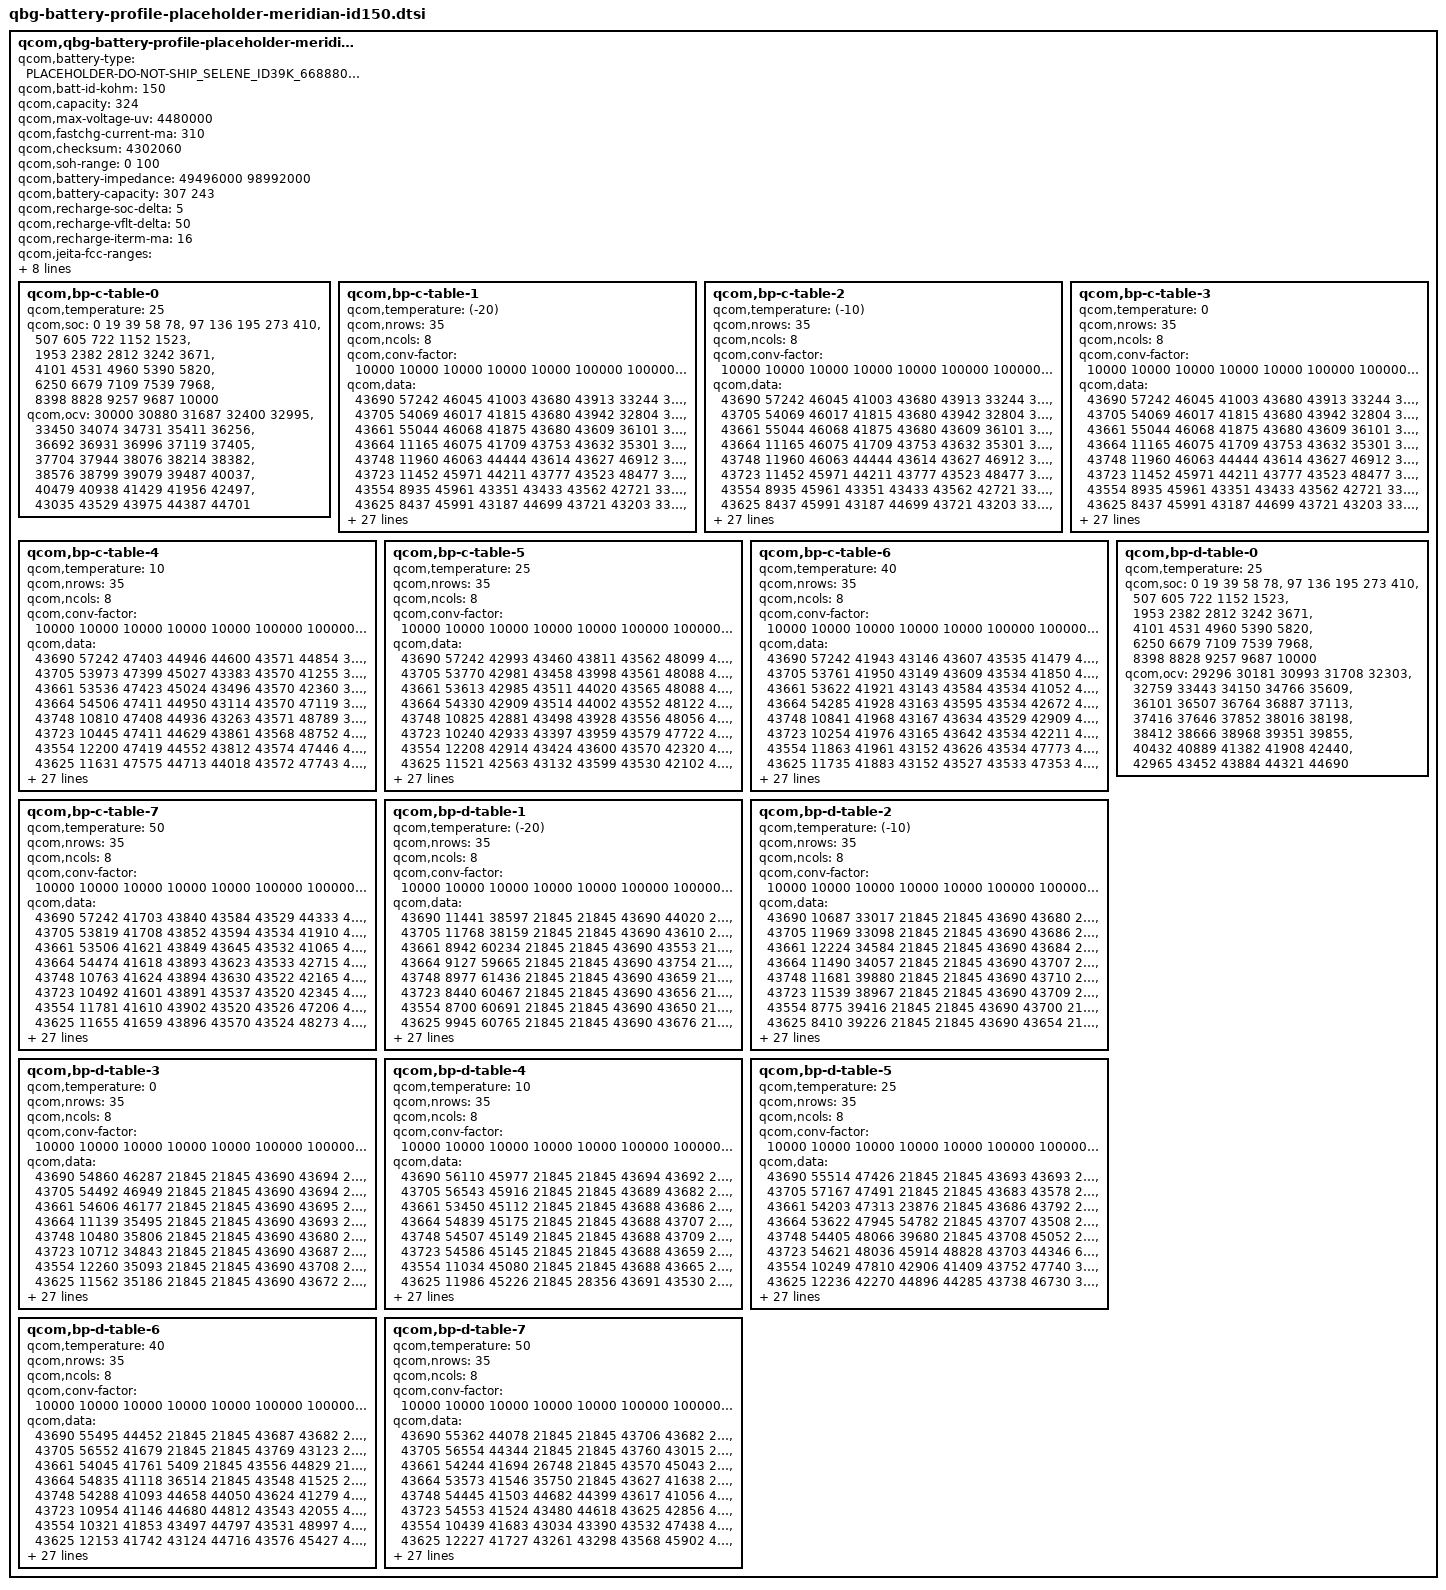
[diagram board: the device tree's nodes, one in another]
/*QBG Profiling Rev. 2.7*/

qcom,qbg-battery-profile-placeholder-meridian-id150 {
	qcom,battery-type = "PLACEHOLDER-DO-NOT-SHIP_SELENE_ID39K_6688801_GOOGLE_310MAH_AVERAGED_MASTERSLAVE_JUL5TH2023";
	qcom,batt-id-kohm = <150>;
	qcom,capacity = <324>;
	qcom,max-voltage-uv = <4480000>;
	qcom,fastchg-current-ma = <310>;
	qcom,checksum = <4302060>; /*@5, 0.005V, 4% */
	qcom,soh-range = <0 100>;
	/*Nominal_Impedance in 10nohm @ SOC 50% 25C* 0:fresh cell, 1: aged cell*/
	qcom,battery-impedance = <49496000 98992000>;
	/*Nominal_Capacity in mAh. 0: fresh cell, 1:aged cell*/ 
	qcom,battery-capacity = <307 243>;
	/*SOC delta (in percent) dropped from EOC SOC to enable recharge*/ 
	qcom,recharge-soc-delta =<5>;
	/*vfloat delta (in mV) dropped from regular vfloat in recharge*/ 
	qcom,recharge-vflt-delta =<50>;
	/*termination current (in mA) in recharge*/ 
	qcom,recharge-iterm-ma = <16>;

	qcom,jeita-fcc-ranges = <0  100 125000
				100 150 175000
				150 250 450000
				250 410 500000
				410 450 125000>;

	qcom,jeita-fv-ranges = <0   100 4480000
				100 150 4480000
				150 250 4480000
				250 410 4480000
				410 450 4480000>;

	/* COOL = 10 DegC, WARM = 41 DegC */
	qcom,jeita-soft-thresholds = <0x2b8a 0x14de>;
	/* COLD = 0 DegC, HOT = 45 DegC */
	qcom,jeita-hard-thresholds = <0x3257 0x128c>;
	/* COOL = 12 DegC, WARM = 39 DegC*/
	qcom,jeita-soft-hys-thresholds = <0x2a0b 0x161b>;
	qcom,jeita-soft-fcc-ua = <125000 125000>;
	qcom,jeita-soft-fv-uv = <4480000 4480000>;

	qcom,bp-c-table-0 {
		qcom,temperature = <25>;
		qcom,soc = <    0    19    39    58    78>,
			<   97   136   195   273   410>,
			<  507   605   722  1152  1523>,
			< 1953  2382  2812  3242  3671>,
			< 4101  4531  4960  5390  5820>,
			< 6250  6679  7109  7539  7968>,
			< 8398  8828  9257  9687 10000>;
		qcom,ocv = <30000 30880 31687 32400 32995>,
			<33450 34074 34731 35411 36256>,
			<36692 36931 36996 37119 37405>,
			<37704 37944 38076 38214 38382>,
			<38576 38799 39079 39487 40037>,
			<40479 40938 41429 41956 42497>,
			<43035 43529 43975 44387 44701>;
	};
	qcom,bp-c-table-1 {
		qcom,temperature = <(-20)>;
		qcom,nrows = <35>;
		qcom,ncols = <8>;
		qcom,conv-factor = <10000 10000 10000 10000 10000 100000 100000 10000>;
		qcom,data = <43690 57242 46045 41003 43680 43913 33244 34599>,
			<43705 54069 46017 41815 43680 43942 32804 34722>,
			<43661 55044 46068 41875 43680 43609 36101 34521>,
			<43664 11165 46075 41709 43753 43632 35301 33149>,
			<43748 11960 46063 44444 43614 43627 46912 33180>,
			<43723 11452 45971 44211 43777 43523 48477 32831>,
			<43554  8935 45961 43351 43433 43562 42721 33734>,
			<43625  8437 45991 43187 44699 43721 43203 33437>,
			<43963  9790 45992 43850 44693 43729 43803 36155>,
			<43824  9725 45680 44006 44782 43576 43976 35881>,
			<43857 15044 45571 43629 44643 43583 43941 35975>,
			<43255 14877 45585 43938 44576 43574 43905 36676>,
			<43128 14965 45627 43930 44763 43530 44015 36683>,
			<44586 15107 45588 43289 43104 43573 44521 35883>,
			<44889 14458 45808 41656 43901 43552 47334 33716>,
			<44299 14687 45745 41917 43157 43566 48855 33644>,
			<41956 15888 48403 41744 43056 43563 47202 33626>,
			<41046 16257 48398 41129 43080 43733 47938 32907>,
			<42496 16189 48598 41116 43403 43732 48051 33009>,
			<42237 15549 48630 41183 43509 43735 48102 32794>,
			<47791 15384 48638 41059 43298 43734 47475 33200>,
			<47897 15657 48614 41381 43303 43734 48505 33254>,
			<47562 12898 48629 41356 43440 43729 45910 32886>,
			<49060 12334 48584 41354 43129 43743 42049 32793>,
			<48150 13964 48483 41244 43422 43719 41116 34452>,
			<45760 14203 45821 42538 43294 43724 41628 33999>,
			<45245 13631 46001 42929 44736 43723 44068 39443>,
			<45423  3013 45949 42759 44996 43764 45038 39383>,
			<47065  2551 45262 42210 44051 43767 44767 40056>,
			<46474  4041 45442 42045 41493 43765 43315 36974>,
			<35428  3544 45406 42414 41227 43720 43455 60036>,
			<35030   984 46670 42409 47862 43726 43051 60731>,
			<36483   400 46907 42028 45649 43725 43199 65188>,
			<36733  1620 46332 41865 34867 43588 43921 63376>,
			<36282  1213 46485 43374 45496 43756 43544 65526>;
	};
	qcom,bp-c-table-2 {
		qcom,temperature = <(-10)>;
		qcom,nrows = <35>;
		qcom,ncols = <8>;
		qcom,conv-factor = <10000 10000 10000 10000 10000 100000 100000 10000>;
		qcom,data = <43690 57242 46045 41003 43680 43913 33244 34599>,
			<43705 54069 46017 41815 43680 43942 32804 34722>,
			<43661 55044 46068 41875 43680 43609 36101 34521>,
			<43664 11165 46075 41709 43753 43632 35301 33149>,
			<43748 11960 46063 44444 43614 43627 46912 33180>,
			<43723 11452 45971 44211 43777 43523 48477 32831>,
			<43554  8935 45961 43351 43433 43562 42721 33734>,
			<43625  8437 45991 43187 44699 43721 43203 33437>,
			<43963  9790 45992 43850 44693 43729 43803 36155>,
			<43824  9725 45680 44006 44782 43576 43976 35881>,
			<43857 15044 45571 43629 44643 43583 43941 35975>,
			<43255 14877 45585 43938 44576 43574 43905 36676>,
			<43128 14965 45627 43930 44763 43530 44015 36683>,
			<44586 15107 45588 43289 43104 43573 44521 35883>,
			<44889 14458 45808 41656 43901 43552 47334 33716>,
			<44299 14687 45745 41917 43157 43566 48855 33644>,
			<41956 15888 48403 41744 43056 43563 47202 33626>,
			<41046 16257 48398 41129 43080 43733 47938 32907>,
			<42496 16189 48598 41116 43403 43732 48051 33009>,
			<42237 15549 48630 41183 43509 43735 48102 32794>,
			<47791 15384 48638 41059 43298 43734 47475 33200>,
			<47897 15657 48614 41381 43303 43734 48505 33254>,
			<47562 12898 48629 41356 43440 43729 45910 32886>,
			<49060 12334 48584 41354 43129 43743 42049 32793>,
			<48150 13964 48483 41244 43422 43719 41116 34452>,
			<45760 14203 45821 42538 43294 43724 41628 33999>,
			<45245 13631 46001 42929 44736 43723 44068 39443>,
			<45423  3013 45949 42759 44996 43764 45038 39383>,
			<47065  2551 45262 42210 44051 43767 44767 40056>,
			<46474  4041 45442 42045 41493 43765 43315 36974>,
			<35428  3544 45406 42414 41227 43720 43455 60036>,
			<35030   984 46670 42409 47862 43726 43051 60731>,
			<36483   400 46907 42028 45649 43725 43199 65188>,
			<36733  1620 46332 41865 34867 43588 43921 63376>,
			<36282  1213 46485 43374 45496 43756 43544 65526>;
	};
	qcom,bp-c-table-3 {
		qcom,temperature = <0>;
		qcom,nrows = <35>;
		qcom,ncols = <8>;
		qcom,conv-factor = <10000 10000 10000 10000 10000 100000 100000 10000>;
		qcom,data = <43690 57242 46045 41003 43680 43913 33244 34599>,
			<43705 54069 46017 41815 43680 43942 32804 34722>,
			<43661 55044 46068 41875 43680 43609 36101 34521>,
			<43664 11165 46075 41709 43753 43632 35301 33149>,
			<43748 11960 46063 44444 43614 43627 46912 33180>,
			<43723 11452 45971 44211 43777 43523 48477 32831>,
			<43554  8935 45961 43351 43433 43562 42721 33734>,
			<43625  8437 45991 43187 44699 43721 43203 33437>,
			<43963  9790 45992 43850 44693 43729 43803 36155>,
			<43824  9725 45680 44006 44782 43576 43976 35881>,
			<43857 15044 45571 43629 44643 43583 43941 35975>,
			<43255 14877 45585 43938 44576 43574 43905 36676>,
			<43128 14965 45627 43930 44763 43530 44015 36683>,
			<44586 15107 45588 43289 43104 43573 44521 35883>,
			<44889 14458 45808 41656 43901 43552 47334 33716>,
			<44299 14687 45745 41917 43157 43566 48855 33644>,
			<41956 15888 48403 41744 43056 43563 47202 33626>,
			<41046 16257 48398 41129 43080 43733 47938 32907>,
			<42496 16189 48598 41116 43403 43732 48051 33009>,
			<42237 15549 48630 41183 43509 43735 48102 32794>,
			<47791 15384 48638 41059 43298 43734 47475 33200>,
			<47897 15657 48614 41381 43303 43734 48505 33254>,
			<47562 12898 48629 41356 43440 43729 45910 32886>,
			<49060 12334 48584 41354 43129 43743 42049 32793>,
			<48150 13964 48483 41244 43422 43719 41116 34452>,
			<45760 14203 45821 42538 43294 43724 41628 33999>,
			<45245 13631 46001 42929 44736 43723 44068 39443>,
			<45423  3013 45949 42759 44996 43764 45038 39383>,
			<47065  2551 45262 42210 44051 43767 44767 40056>,
			<46474  4041 45442 42045 41493 43765 43315 36974>,
			<35428  3544 45406 42414 41227 43720 43455 60036>,
			<35030   984 46670 42409 47862 43726 43051 60731>,
			<36483   400 46907 42028 45649 43725 43199 65188>,
			<36733  1620 46332 41865 34867 43588 43921 63376>,
			<36282  1213 46485 43374 45496 43756 43544 65526>;
	};
	qcom,bp-c-table-4 {
		qcom,temperature = <10>;
		qcom,nrows = <35>;
		qcom,ncols = <8>;
		qcom,conv-factor = <10000 10000 10000 10000 10000 100000 100000 10000>;
		qcom,data = <43690 57242 47403 44946 44600 43571 44854 34827>,
			<43705 53973 47399 45027 43383 43570 41255 35002>,
			<43661 53536 47423 45024 43496 43570 42360 35804>,
			<43664 54506 47411 44950 43114 43570 47119 35442>,
			<43748 10810 47408 44936 43263 43571 48789 35474>,
			<43723 10445 47411 44629 43861 43568 48752 46385>,
			<43554 12200 47419 44552 43812 43574 47446 46288>,
			<43625 11631 47575 44713 44018 43572 47743 47081>,
			<43963  8251 47493 43108 43167 43573 44587 46808>,
			<43824 10055 47173 43212 43164 43526 43506 45522>,
			<43857  9520 47178 43244 43158 43538 43484 45500>,
			<43255 15070 47120 43592 43508 43596 44018 45104>,
			<43128 14849 47154 43960 43494 43636 43981 45268>,
			<44586 15254 47144 44777 43972 43532 42873 45375>,
			<44889 14537 47250 44883 43887 43552 47991 47024>,
			<44299 14628 47936 44230 43139 43565 47160 47095>,
			<41956 16093 47921 44131 43160 43566 47115 47074>,
			<41046 15942 48077 44118 43256 43566 47960 47072>,
			<42496 16334 48020 44448 43050 43561 42283 47078>,
			<42237 16220 48053 44462 43128 43563 42551 47043>,
			<47791 15369 48034 44452 43408 43733 42743 46879>,
			<47897 15809 47706 44525 43306 43732 42065 46216>,
			<47562 13016 47739 44290 43472 43563 45605 46310>,
			<49060 12473 47632 44402 43026 43566 35584 46860>,
			<48150 14068 47643 44472 43140 43734 41169 46825>,
			<45760 13476 47628 44528 43261 43741 41907 46618>,
			<45245 13689 47621 44301 43054 43737 44374 47080>,
			<45423  2847 47706 41513 43448 43713 44247 46500>,
			<47065  2328 48118 41873 43383 43714 45046 35739>,
			<46474  3950 47951 41855 44613 43714 44599 35084>,
			<35428  3443 47144 41195 44044 43712 43341 35914>,
			<35030   889 47491 41206 41787 43716 43405 33256>,
			<36483   316 47473 41122 42368 43743 43048 39145>,
			<36733  1942 48665 44371 49000 43533 43888 37871>,
			<36282  1230 48944 44544 48832 43727 43937 40241>;
	};
	qcom,bp-c-table-5 {
		qcom,temperature = <25>;
		qcom,nrows = <35>;
		qcom,ncols = <8>;
		qcom,conv-factor = <10000 10000 10000 10000 10000 100000 100000 10000>;
		qcom,data = <43690 57242 42993 43460 43811 43562 48099 48895>,
			<43705 53770 42981 43458 43998 43561 48088 48830>,
			<43661 53613 42985 43511 44020 43565 48088 47482>,
			<43664 54330 42909 43514 44002 43552 48122 47399>,
			<43748 10825 42881 43498 43928 43556 48056 47584>,
			<43723 10240 42933 43397 43959 43579 47722 47520>,
			<43554 12208 42914 43424 43600 43570 42320 47166>,
			<43625 11521 42563 43132 43599 43530 42102 47268>,
			<43963  8441 42601 43047 43602 43521 41865 47883>,
			<43824  9994 42551 43165 43910 43536 44895 48110>,
			<43857  9726 42541 43199 43908 43626 44886 47708>,
			<43255 15081 42716 43150 43624 43536 41255 47649>,
			<43128 14894 42697 43154 43520 43548 42805 47834>,
			<44586 14933 42644 43036 43969 43522 41798 47904>,
			<44889 14519 42671 43497 43872 43583 41098 47340>,
			<44299 14818 41341 43306 43857 43570 41286 47144>,
			<41956 16018 41223 43288 43799 43583 42247 47335>,
			<41046 15894 41262 43366 43804 43577 42331 47260>,
			<42496 16364 41461 43330 43876 43583 42888 47331>,
			<42237 16196 41364 43297 43222 43578 44111 47317>,
			<47791 15386 41358 43464 43416 43552 44200 47218>,
			<47897 15653 41383 43476 43456 43565 44518 47511>,
			<47562 12813 41040 43359 43495 43553 42807 47613>,
			<49060 12437 41030 44698 43218 43576 47915 47176>,
			<48150 14031 41026 43331 43795 43554 41852 47981>,
			<45760 13493 41038 43367 43841 43563 44244 47985>,
			<45245 13632 41026 44718 43146 43729 45009 47345>,
			<45423  2943 41031 44769 43201 43740 44563 47531>,
			<47065  2382 41043 44567 43060 43741 44589 47383>,
			<46474  3243 41399 44918 43450 43743 44549 49107>,
			<35428   689 41422 44271 44683 43741 44722 48579>,
			<35030   163 41239 44088 44816 43732 43316 45836>,
			<36483   365 42627 44093 41878 43556 43402 46850>,
			<36733  1993 42524 44667 44290 43578 43380 45144>,
			<36282  1079 42776 43107 42372 43561 43929 35588>;
	};
	qcom,bp-c-table-6 {
		qcom,temperature = <40>;
		qcom,nrows = <35>;
		qcom,ncols = <8>;
		qcom,conv-factor = <10000 10000 10000 10000 10000 100000 100000 10000>;
		qcom,data = <43690 57242 41943 43146 43607 43535 41479 42790>,
			<43705 53761 41950 43149 43609 43534 41850 42964>,
			<43661 53622 41921 43143 43584 43534 41052 42949>,
			<43664 54285 41928 43163 43595 43534 42672 42955>,
			<43748 10841 41968 43167 43634 43529 42909 43000>,
			<43723 10254 41976 43165 43642 43534 42211 42990>,
			<43554 11863 41961 43152 43626 43534 47773 42895>,
			<43625 11735 41883 43152 43527 43533 47353 42589>,
			<43963  8380 41866 43148 43568 43524 48815 42526>,
			<43824 10226 41888 43191 43581 43548 47104 42540>,
			<43857  9656 41899 43901 43533 43619 42160 42647>,
			<43255 15024 41552 43983 43542 43632 41791 41313>,
			<43128 15042 41560 43976 43529 43641 41317 41221>,
			<44586 14949 41550 43884 43823 43629 44270 42579>,
			<44889 15170 41573 43847 43879 43537 44204 42997>,
			<44299 14779 41494 43149 43851 43538 41606 42801>,
			<41956 14684 41475 43241 43828 43544 42857 42946>,
			<41046 15927 41533 43141 43980 43524 42638 42943>,
			<42496 16272 41518 43219 44020 43534 41459 42978>,
			<42237 16199 41669 43214 43850 43525 44261 42783>,
			<47791 15380 41718 43901 43089 43544 43342 42162>,
			<47897 15619 41700 43877 43493 43526 44582 42203>,
			<47562 12903 41705 43152 43443 43532 41584 42207>,
			<49060 12510 41622 43229 43174 43535 42751 42853>,
			<48150 14034 41619 43253 43979 43535 41180 42565>,
			<45760 13463 41629 43189 43835 43528 44633 42573>,
			<45245  2720 41629 43207 43780 43570 44640 42944>,
			<45423  2896 41619 43117 43854 43557 44569 42148>,
			<47065  3756 41620 43449 43154 43554 44679 42089>,
			<46474  3252 41699 43318 43254 43563 44544 42283>,
			<35428   667 41719 44732 43455 43734 43333 47733>,
			<35030   191 41684 44592 43354 43555 44731 47359>,
			<36483   357 41475 44558 44865 43529 43369 48684>,
			<36733  2014 41536 43399 44565 43575 44792 47952>,
			<36282  1049 41774 43235 42676 43544 43817 45952>;
	};
	qcom,bp-c-table-7 {
		qcom,temperature = <50>;
		qcom,nrows = <35>;
		qcom,ncols = <8>;
		qcom,conv-factor = <10000 10000 10000 10000 10000 100000 100000 10000>;
		qcom,data = <43690 57242 41703 43840 43584 43529 44333 42662>,
			<43705 53819 41708 43852 43594 43534 41910 41309>,
			<43661 53506 41621 43849 43645 43532 41065 41288>,
			<43664 54474 41618 43893 43623 43533 42715 41319>,
			<43748 10763 41624 43894 43630 43522 42165 41234>,
			<43723 10492 41601 43891 43537 43520 42345 41225>,
			<43554 11781 41610 43902 43520 43526 47206 41431>,
			<43625 11655 41659 43896 43570 43524 48273 41471>,
			<43963  9065 41646 43900 43555 43546 46069 41363>,
			<43824 10157 44377 43799 43561 43537 48172 41041>,
			<43857  9320 44353 43827 43577 43620 47723 41086>,
			<43255  9587 44364 43967 43523 43615 41861 41190>,
			<43128 15000 44363 43944 43569 43609 41154 41090>,
			<44586 14907 44402 43818 43983 43635 44884 41256>,
			<44889 15119 44390 43833 43835 43644 44895 41244>,
			<44299 14463 44395 43828 43804 43647 44089 41290>,
			<41956 14614 44319 43787 43803 43640 41790 41339>,
			<41046 15912 44291 43815 44026 43617 41972 41457>,
			<42496 16263 44343 43876 43935 43538 41756 41251>,
			<42237 16204 44324 43194 43987 43543 44453 42659>,
			<47791 15380 44331 44021 43033 43646 43483 42713>,
			<47897 15643 44508 43925 43446 43617 43368 42513>,
			<47562 12874 44484 43815 43083 43626 44522 42523>,
			<49060 12321 44483 43890 43873 43540 42679 42665>,
			<48150 13867 44492 43896 43904 43543 41241 41454>,
			<45760 13539 44494 43788 44009 43538 45015 41367>,
			<45245  2737 44494 43891 43997 43526 44651 41234>,
			<45423  2213 44489 43188 43801 43531 44796 42727>,
			<47065  3763 44493 43065 43902 43583 44633 42589>,
			<46474  3226 44487 43098 43177 43556 44942 42814>,
			<35428   657 44508 43474 43213 43567 44639 42044>,
			<35030   181 44322 43323 43496 43552 44689 42248>,
			<36483   369 44302 43299 44660 43574 43271 48018>,
			<36733  2002 44390 43016 43272 43520 44941 42378>,
			<36282  1130 41620 43998 41591 43621 44018 47390>;
	};
	qcom,bp-d-table-0 {
		qcom,temperature = <25>;
		qcom,soc = <    0    19    39    58    78>,
			<   97   136   195   273   410>,
			<  507   605   722  1152  1523>,
			< 1953  2382  2812  3242  3671>,
			< 4101  4531  4960  5390  5820>,
			< 6250  6679  7109  7539  7968>,
			< 8398  8828  9257  9687 10000>;
		qcom,ocv = <29296 30181 30993 31708 32303>,
			<32759 33443 34150 34766 35609>,
			<36101 36507 36764 36887 37113>,
			<37416 37646 37852 38016 38198>,
			<38412 38666 38968 39351 39855>,
			<40432 40889 41382 41908 42440>,
			<42965 43452 43884 44321 44690>;
	};
	qcom,bp-d-table-1 {
		qcom,temperature = <(-20)>;
		qcom,nrows = <35>;
		qcom,ncols = <8>;
		qcom,conv-factor = <10000 10000 10000 10000 10000 100000 100000 10000>;
		qcom,data = <43690 11441 38597 21845 21845 43690 44020 21845>,
			<43705 11768 38159 21845 21845 43690 43610 21845>,
			<43661  8942 60234 21845 21845 43690 43553 21845>,
			<43664  9127 59665 21845 21845 43690 43754 21845>,
			<43748  8977 61436 21845 21845 43690 43659 21845>,
			<43723  8440 60467 21845 21845 43690 43656 21845>,
			<43554  8700 60691 21845 21845 43690 43650 21845>,
			<43625  9945 60765 21845 21845 43690 43676 21845>,
			<43963 10179 60735 21845 18154 43690 43770 21845>,
			<43824  9410 60480 21845 50402 43690 43554 21845>,
			<43857  9335 61424 21845 58345 43690 43538 21845>,
			<43255  9618 59792 21845 39247 43690 43585 21845>,
			<43128  9525 60361 21845 36472 43690 44000 21845>,
			<44586 14874 37016 15248 48556 43691 43217 21845>,
			<44889 15308 37786 49431 45501 43691 43102 21845>,
			<44299 15199 40755 57586 48384 43688 43429 21845>,
			<41956 14379 39331 40399 47211 43689 43483 32111>,
			<41046 14776 39543 33182 41984 43694 43380  7668>,
			<42496 14598 34275 35301 41284 43695 44678  2958>,
			<42237 16118 33953 46957 41124 43692 44751 14910>,
			<47791 16308 34703 46076 41542 43693 44747 10592>,
			<47897 16209 33099 48260 44355 43683 44592 54027>,
			<47562 15447 33186 48748 44225 43681 44266 56067>,
			<49060 13038 32989 48874 44918 43686 41670 51188>,
			<48150 13176 32898 47475 44218 43684 41191 49649>,
			<45760 12605 32930 47571 44057 43706 41401 49574>,
			<45245 14126 33606 47559 44301 43704 41359 49606>,
			<45423 13619 33656 47482 41683 43711 41404 50916>,
			<47065  2938 33556 47455 41504 43669 42757 51158>,
			<46474  3758 33542 48737 41904 43669 42144 50207>,
			<35428  3207 33587 49144 41752 43668 42788 50545>,
			<35030   663 33747 49147 41754 43775 42533 55864>,
			<36483   153 33770 48946 41549 43770 41159 55975>,
			<36733   325 33351 48610 44052 43693 44874 51098>,
			<36282  1930 33285 45627 44846 43690 43394 49544>;
	};
	qcom,bp-d-table-2 {
		qcom,temperature = <(-10)>;
		qcom,nrows = <35>;
		qcom,ncols = <8>;
		qcom,conv-factor = <10000 10000 10000 10000 10000 100000 100000 10000>;
		qcom,data = <43690 10687 33017 21845 21845 43690 43680 21845>,
			<43705 11969 33098 21845 21845 43690 43686 21845>,
			<43661 12224 34584 21845 21845 43690 43684 21845>,
			<43664 11490 34057 21845 21845 43690 43707 21845>,
			<43748 11681 39880 21845 21845 43690 43710 21845>,
			<43723 11539 38967 21845 21845 43690 43709 21845>,
			<43554  8775 39416 21845 21845 43690 43700 21845>,
			<43625  8410 39226 21845 21845 43690 43654 21845>,
			<43963  9877 39333 21845     3 43690 43768 21845>,
			<43824  9415 39817 21845 40756 43690 43607 21845>,
			<43857  9610 34099 21845 46200 43690 43819 21845>,
			<43255  9516 34604 25584 48654 43690 43192 21845>,
			<43128  9587 33234 50113 42951 43691 43112 21845>,
			<44586 14918 36716 45683 44194 43689 45026 14611>,
			<44889 15139 36539 45217 41916 43695 44786 11758>,
			<44299 14512 35050 48640 44343 43683 44642 50413>,
			<41956 14387 35724 47784 44206 43706 44954 62683>,
			<41046 14768 35330 42947 44578 43657 44280 65307>,
			<42496 14604 35539 42656 43277 43669 44333 64025>,
			<42237 16119 35525 41391 43458 43746 41536 59380>,
			<47791 16357 35562 41024 43077 43717 42033 57655>,
			<47897 15423 35576 41360 43512 43728 48984 57790>,
			<47562 15694 35476 41443 43343 43735 47389 57347>,
			<49060 13304 35553 41438 44736 43562 47680 57406>,
			<48150 12381 35564 41306 44621 43563 47795 57442>,
			<45760 13945 35477 42549 45009 43563 42280 57797>,
			<45245 13436 35555 42998 44197 43734 42191 59009>,
			<45423  2651 35511 42224 44231 43740 42165 59265>,
			<47065  2484 35465 42477 44098 43717 42848 58618>,
			<46474  4066 35505 47780 44488 43725 42589 58671>,
			<35428  3577 35492 47739 44391 43722 41326 64121>,
			<35030   909 46450 48078 44397 43763 41815 64331>,
			<36483   122 46387 47977 44114 43749 41536 64325>,
			<36733  1557 46535 47967 44790 43752 41672 64125>,
			<36282  1036 46541 47937 43429 43676 41724 58849>;
	};
	qcom,bp-d-table-3 {
		qcom,temperature = <0>;
		qcom,nrows = <35>;
		qcom,ncols = <8>;
		qcom,conv-factor = <10000 10000 10000 10000 10000 100000 100000 10000>;
		qcom,data = <43690 54860 46287 21845 21845 43690 43694 21845>,
			<43705 54492 46949 21845 21845 43690 43694 21845>,
			<43661 54606 46177 21845 21845 43690 43695 21845>,
			<43664 11139 35495 21845 21845 43690 43693 21845>,
			<43748 10480 35806 21845 21845 43690 43680 21845>,
			<43723 10712 34843 21845 21845 43690 43687 21845>,
			<43554 12260 35093 21845 21845 43690 43708 21845>,
			<43625 11562 35186 21845 21845 43690 43672 21845>,
			<43963  9085 35230 21845 10917 43690 43729 21845>,
			<43824 10153 35762 21845 45680 43690 43834 21845>,
			<43857  9279 46356 53993 42123 43690 43228 21845>,
			<43255  9715 46182 37747 41931 43691 43303 16565>,
			<43128  9498 46865 46770 44208 43688 44590  3867>,
			<44586 15040 45125 41696 43443 43683 44174 64396>,
			<44889 15263 45894 41793 43016 43703 41774 57737>,
			<44299 14542 46066 41934 43094 43745 45594 61065>,
			<41956 14731 45959 41511 43411 43743 45121 38308>,
			<41046 14628 46057 41630 43083 43729 48304 36970>,
			<42496 16044 45993 44356 43066 43732 47939 40220>,
			<42237 15970 45982 44383 43040 43561 47436 40127>,
			<47791 16149 45993 41643 43122 43567 48890 40845>,
			<47897 15462 45989 41641 43392 43564 48040 40690>,
			<47562 12968 45966 41613 43480 43554 42182 39256>,
			<49060 13252 45960 41505 43281 43554 43005 39238>,
			<48150 12724 45652 41869 44680 43567 42912 40603>,
			<45760 14268 45687 41797 44569 43733 42577 40528>,
			<45245 13727 45684 41079 44950 43730 42524 40077>,
			<45423  3020 45648 41232 44818 43739 42559 40435>,
			<47065  2519 45597 42628 44208 43725 41163 37514>,
			<46474  3899 45676 42556 44233 43722 41576 37460>,
			<35428  3391 45578 42938 44224 43760 41601 37740>,
			<35030   985 45631 42762 44169 43773 41674 37082>,
			<36483   445 45626 42851 45035 43769 41589 37057>,
			<36733  1615 45780 43003 43322 43747 41956 37863>,
			<36282  1036 45763 42510 43247 43752 41762 40284>;
	};
	qcom,bp-d-table-4 {
		qcom,temperature = <10>;
		qcom,nrows = <35>;
		qcom,ncols = <8>;
		qcom,conv-factor = <10000 10000 10000 10000 10000 100000 100000 10000>;
		qcom,data = <43690 56110 45977 21845 21845 43694 43692 21845>,
			<43705 56543 45916 21845 21845 43689 43682 21845>,
			<43661 53450 45112 21845 21845 43688 43686 21845>,
			<43664 54839 45175 21845 21845 43688 43707 21845>,
			<43748 54507 45149 21845 21845 43688 43709 21845>,
			<43723 54586 45145 21845 21845 43688 43659 21845>,
			<43554 11034 45080 21845 21845 43688 43665 21845>,
			<43625 11986 45226 21845 28356 43691 43530 21845>,
			<43963 11773 45649  5426 34230 43690 43831 21845>,
			<43824  8631 48600 33552 41951 43691 44769  5639>,
			<43857 10140 48150 47986 44631 43689 44231 54775>,
			<43255  9236 48989 41052 43272 43695 41953 63042>,
			<43128  9694 49034 44354 43106 43708 41763 60545>,
			<44586 15032 48682 44647 43990 43772 41011 33873>,
			<44889 15276 48777 44862 43848 43725 43002 34504>,
			<44299 14571 47413 44823 43114 43561 42038 33722>,
			<41956 14776 47554 44901 43444 43559 42483 35863>,
			<41046 14650 47587 44825 43113 43579 42000 36571>,
			<42496 16030 47516 44910 43056 43577 48062 35219>,
			<42237 15957 47540 44907 43038 43577 47634 35058>,
			<47791 16241 47533 44831 43028 43576 42758 35625>,
			<47897 15478 47186 44902 43025 43576 42744 35422>,
			<47562 12964 47180 44201 43106 43578 41272 35427>,
			<49060 13265 47206 44256 43100 43558 41469 35442>,
			<48150 12693 47124 44159 43495 43553 42595 35798>,
			<45760 14275 47120 44305 43335 43558 47656 34887>,
			<45245 13569 47164 41719 44546 43555 48117 36588>,
			<45423  2869 47165 41664 44626 43729 41464 36451>,
			<47065  2359 47119 41673 44943 43736 44409 36756>,
			<46474  3865 47123 41587 44663 43737 44407 36710>,
			<35428  3344 47121 41861 44596 43739 44356 36046>,
			<35030   818 47208 41933 44796 43719 41524 35959>,
			<36483   406 47225 41970 43331 43724 41878 35929>,
			<36733  1616 47194 41477 43492 43773 41966 35890>,
			<36282  1078 47532 41610 43132 43750 41899 36724>;
	};
	qcom,bp-d-table-5 {
		qcom,temperature = <25>;
		qcom,nrows = <35>;
		qcom,ncols = <8>;
		qcom,conv-factor = <10000 10000 10000 10000 10000 100000 100000 10000>;
		qcom,data = <43690 55514 47426 21845 21845 43693 43693 21845>,
			<43705 57167 47491 21845 21845 43683 43578 21845>,
			<43661 54203 47313 23876 21845 43686 43792 21845>,
			<43664 53622 47945 54782 21845 43707 43508 21845>,
			<43748 54405 48066 39680 21845 43708 45052 21845>,
			<43723 54621 48036 45914 48828 43703 44346 64986>,
			<43554 10249 47810 42906 41409 43752 47740 39940>,
			<43625 12236 42270 44896 44285 43738 46730 36553>,
			<43963 11620 42467 44648 44796 43735 46372 46190>,
			<43824  8627 42099 44678 43235 43552 46375 45217>,
			<43857 10159 42198 43361 43827 43556 45850 48387>,
			<43255  9265 42130 43272 43839 43556 42785 48128>,
			<43128  9526 42155 43361 43807 43530 41438 48383>,
			<44586 15037 42968 43035 43643 43569 42274 47174>,
			<44889 14931 42911 43100 43991 43581 41387 47583>,
			<44299 14466 42605 43496 43196 43533 41180 47364>,
			<41956 14756 42705 43504 43014 43520 41090 47432>,
			<41046 14710 42728 43327 43126 43536 43004 48810>,
			<42496 15914 42662 43467 43083 43544 41153 47397>,
			<42237 16284 41290 43505 43060 43547 41765 47529>,
			<47791 15526 41237 43471 43165 43526 41751 47319>,
			<47897 15776 41224 43457 43853 43532 41107 47288>,
			<47562 12946 41251 43463 43900 43573 40992 47942>,
			<49060 13085 41437 43325 43846 43573 42912 47292>,
			<48150 12549 41410 44731 43068 43523 47967 47599>,
			<45760 14170 41458 44768 43293 43522 47290 48675>,
			<45245 13587 41470 44717 43379 43578 41741 48837>,
			<45423  2828 41459 43353 43288 43579 44149 48878>,
			<47065  2334 41414 44781 43397 43571 44465 48785>,
			<46474  3938 41248 44582 43016 43568 44498 48783>,
			<35428  3455 41221 44655 43199 43581 41894 48825>,
			<35030   790 41329 44570 43860 43576 41812 48804>,
			<36483   454 42680 44751 43175 43579 40998 48821>,
			<36733  1931 42738 44733 43142 43581 41263 48872>,
			<36282  1080 42555 43383 43243 43531 42680 48838>;
	};
	qcom,bp-d-table-6 {
		qcom,temperature = <40>;
		qcom,nrows = <35>;
		qcom,ncols = <8>;
		qcom,conv-factor = <10000 10000 10000 10000 10000 100000 100000 10000>;
		qcom,data = <43690 55495 44452 21845 21845 43687 43682 21845>,
			<43705 56552 41679 21845 21845 43769 43123 21845>,
			<43661 54045 41761  5409 21845 43556 44829 21845>,
			<43664 54835 41118 36514 21845 43548 41525 21845>,
			<43748 54288 41093 44658 44050 43624 41279 48597>,
			<43723 10954 41146 44680 44812 43543 42055 49124>,
			<43554 10321 41853 43497 44797 43531 48997 47119>,
			<43625 12153 41742 43124 44716 43576 45427 47902>,
			<43963  8923 41943 43027 44729 43580 46354 48124>,
			<43824  8696 41981 43023 43865 43572 35006 42054>,
			<43857 10174 41966 43043 43962 43534 46855 42850>,
			<43255  9229 41884 43057 43937 43529 42482 42851>,
			<43128  9477 41861 43440 43965 43522 42190 42228>,
			<44586 15010 41892 43792 43530 43536 42369 42641>,
			<44889 14961 41566 43845 43934 43631 40977 42565>,
			<44299 14504 41573 43244 43839 43630 41795 42792>,
			<41956 14424 41488 43259 43860 43628 41753 42870>,
			<41046 14669 41485 43235 43029 43646 41472 42025>,
			<42496 15934 41534 43014 43240 43953 41130 42231>,
			<42237 16358 41512 43023 43856 43605 41816 42155>,
			<47791 15501 41688 43058 43800 43638 41422 42800>,
			<47897 15752 41678 43230 43969 43631 41331 42934>,
			<47562 13037 41715 43157 44022 43542 41259 42618>,
			<49060 13168 41722 43258 43787 43540 42171 42890>,
			<48150 12608 41698 43056 43119 43625 47503 42020>,
			<45760 14183 41705 43239 43303 43524 41523 42406>,
			<45245 13623 41704 43242 43300 43526 44188 42409>,
			<45423  2849 41710 43028 43109 43624 44155 42108>,
			<47065  2338 41698 43513 43898 43616 41912 42196>,
			<46474  3901 41726 43489 43969 43523 41971 42112>,
			<35428  3337 41678 43401 43907 43581 40987 42872>,
			<35030   804 41695 43127 43915 43570 42626 42786>,
			<36483   482 41504 43064 43920 43531 42652 42948>,
			<36733  1962 41481 43232 43813 43546 41146 42972>,
			<36282  1231 41501 43150 43795 43543 44529 42800>;
	};
	qcom,bp-d-table-7 {
		qcom,temperature = <50>;
		qcom,nrows = <35>;
		qcom,ncols = <8>;
		qcom,conv-factor = <10000 10000 10000 10000 10000 100000 100000 10000>;
		qcom,data = <43690 55362 44078 21845 21845 43706 43682 21845>,
			<43705 56554 44344 21845 21845 43760 43015 21845>,
			<43661 54244 41694 26748 21845 43570 45043 21845>,
			<43664 53573 41546 35750 21845 43627 41638 21845>,
			<43748 54445 41503 44682 44399 43617 41056 48265>,
			<43723 54553 41524 43480 44618 43625 42856 47253>,
			<43554 10439 41683 43034 43390 43532 47438 47807>,
			<43625 12227 41727 43261 43298 43568 45902 42468>,
			<43963  8847 41629 43160 43303 43572 46126 42064>,
			<43824  8630 41660 43151 43180 43535 35220 42904>,
			<43857  9852 41644 43186 43955 43520 34861 42678>,
			<43255  9418 44372 43143 43587 43533 49027 42666>,
			<43128  9684 44371 43041 43952 43530 41426 42559>,
			<44586  9550 44361 43998 43567 43631 47304 40972>,
			<44889 14853 44411 43777 43603 43636 42905 41375>,
			<44299 15216 44310 43174 43933 43638 42568 41312>,
			<41956 14447 44292 43889 43839 43599 41148 41333>,
			<41046 14689 44303 43196 43195 43927 41859 42559>,
			<42496 15872 44339 43067 43860 43922 42914 42579>,
			<42237 16321 44327 43260 43857 43940 41099 42515>,
			<47791 15509 44331 43158 43800 43599 41102 42641>,
			<47897 15768 44498 43193 44011 43645 41070 41266>,
			<47562 13053 44506 43851 43917 43640 42665 41455>,
			<49060 13127 44482 43854 43994 43643 42192 41274>,
			<48150 12635 44491 43863 43034 43642 42233 42570>,
			<45760 14177 44535 43792 43516 43619 44098 42983>,
			<45245 13620 44534 43192 43100 43622 44278 42980>,
			<45423  3028 44490 43124 43886 43944 41913 42926>,
			<47065  2518 44494 43089 44014 43630 41197 42500>,
			<46474  3878 44480 43074 43592 43531 42229 42727>,
			<35428  3391 44504 43019 43631 43573 47663 41283>,
			<35030   980 44502 43240 43620 43532 42292 41277>,
			<36483   403 44323 43856 43601 43549 42788 41428>,
			<36733  1627 44338 43902 44013 43621 41238 41267>,
			<36282  1275 44302 43889 43817 43593 41008 41289>;
	};
};
